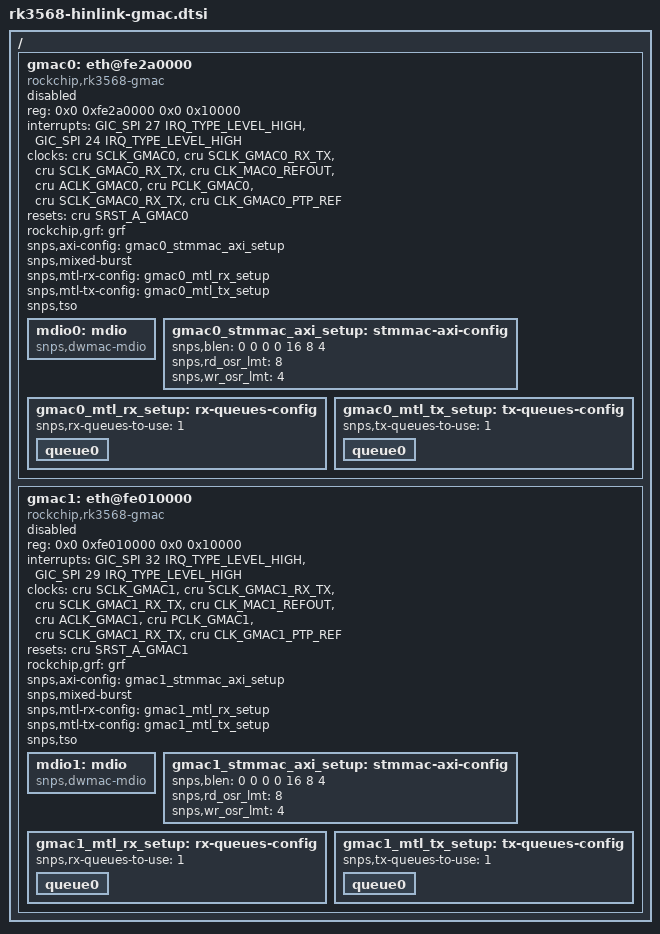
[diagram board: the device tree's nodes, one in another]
// SPDX-License-Identifier: (GPL-2.0+ OR MIT)
/*
* Copyright (c) 2021 Rockchip Electronics Co., Ltd.
* Copyright (c) 2022 EmbedFire <embedfire@embedfire.com>
*/

/dts-v1/;
#include <dt-bindings/gpio/gpio.h>
#include <dt-bindings/leds/common.h>
#include <dt-bindings/pinctrl/rockchip.h>
#include <dt-bindings/soc/rockchip,vop2.h>
#include "rk3568.dtsi"

/delete-node/ &gmac0;
/delete-node/ &gmac1;

/ {
	gmac0: eth@fe2a0000 {
		compatible = "rockchip,rk3568-gmac", "snps,dwmac-4.20a";
		reg = <0x0 0xfe2a0000 0x0 0x10000>;
		interrupts = <GIC_SPI 27 IRQ_TYPE_LEVEL_HIGH>,
			     <GIC_SPI 24 IRQ_TYPE_LEVEL_HIGH>;
		interrupt-names = "macirq", "eth_wake_irq";
		clocks = <&cru SCLK_GMAC0>, <&cru SCLK_GMAC0_RX_TX>,
			 <&cru SCLK_GMAC0_RX_TX>, <&cru CLK_MAC0_REFOUT>,
			 <&cru ACLK_GMAC0>, <&cru PCLK_GMAC0>,
			 <&cru SCLK_GMAC0_RX_TX>, <&cru CLK_GMAC0_PTP_REF>;
		clock-names = "stmmaceth", "mac_clk_rx",
			      "mac_clk_tx", "clk_mac_refout",
			      "aclk_mac", "pclk_mac",
			      "clk_mac_speed", "ptp_ref";
		resets = <&cru SRST_A_GMAC0>;
		reset-names = "stmmaceth";
		rockchip,grf = <&grf>;
		snps,axi-config = <&gmac0_stmmac_axi_setup>;
		snps,mixed-burst;
		snps,mtl-rx-config = <&gmac0_mtl_rx_setup>;
		snps,mtl-tx-config = <&gmac0_mtl_tx_setup>;
		snps,tso;
		status = "disabled";

		mdio0: mdio {
			compatible = "snps,dwmac-mdio";
			#address-cells = <0x1>;
			#size-cells = <0x0>;
		};

		gmac0_stmmac_axi_setup: stmmac-axi-config {
			snps,blen = <0 0 0 0 16 8 4>;
			snps,rd_osr_lmt = <8>;
			snps,wr_osr_lmt = <4>;
		};

		gmac0_mtl_rx_setup: rx-queues-config {
			snps,rx-queues-to-use = <1>;
			queue0 {};
		};

		gmac0_mtl_tx_setup: tx-queues-config {
			snps,tx-queues-to-use = <1>;
			queue0 {};
		};
	};

	gmac1: eth@fe010000 {
		compatible = "rockchip,rk3568-gmac", "snps,dwmac-4.20a";
		reg = <0x0 0xfe010000 0x0 0x10000>;
		interrupts = <GIC_SPI 32 IRQ_TYPE_LEVEL_HIGH>,
			     <GIC_SPI 29 IRQ_TYPE_LEVEL_HIGH>;
		interrupt-names = "macirq", "eth_wake_irq";
		clocks = <&cru SCLK_GMAC1>, <&cru SCLK_GMAC1_RX_TX>,
			 <&cru SCLK_GMAC1_RX_TX>, <&cru CLK_MAC1_REFOUT>,
			 <&cru ACLK_GMAC1>, <&cru PCLK_GMAC1>,
			 <&cru SCLK_GMAC1_RX_TX>, <&cru CLK_GMAC1_PTP_REF>;
		clock-names = "stmmaceth", "mac_clk_rx",
			      "mac_clk_tx", "clk_mac_refout",
			      "aclk_mac", "pclk_mac",
			      "clk_mac_speed", "ptp_ref";
		resets = <&cru SRST_A_GMAC1>;
		reset-names = "stmmaceth";
		rockchip,grf = <&grf>;
		snps,axi-config = <&gmac1_stmmac_axi_setup>;
		snps,mixed-burst;
		snps,mtl-rx-config = <&gmac1_mtl_rx_setup>;
		snps,mtl-tx-config = <&gmac1_mtl_tx_setup>;
		snps,tso;
		status = "disabled";

		mdio1: mdio {
			compatible = "snps,dwmac-mdio";
			#address-cells = <0x1>;
			#size-cells = <0x0>;
		};

		gmac1_stmmac_axi_setup: stmmac-axi-config {
			snps,blen = <0 0 0 0 16 8 4>;
			snps,rd_osr_lmt = <8>;
			snps,wr_osr_lmt = <4>;
		};

		gmac1_mtl_rx_setup: rx-queues-config {
			snps,rx-queues-to-use = <1>;
			queue0 {};
		};

		gmac1_mtl_tx_setup: tx-queues-config {
			snps,tx-queues-to-use = <1>;
			queue0 {};
		};
	};
};
